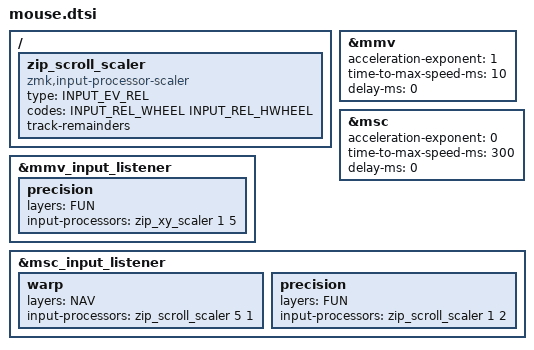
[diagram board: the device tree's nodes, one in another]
// Settings tuned for 3840 x 2160 display resolution
#define ZMK_POINTING_DEFAULT_MOVE_VAL 3000 // 600
#define ZMK_POINTING_DEFAULT_SCRL_VAL 20  // 10

#include <dt-bindings/zmk/pointing.h>
#include <input/processors.dtsi>
#include <zephyr/dt-bindings/input/input-event-codes.h>

// Based on @caksoylar's config, defaults in comments
&mmv {
  acceleration-exponent = <1>;          // 1
  time-to-max-speed-ms = <10>;          // 300
  delay-ms = <0>;                       // 0
};

&msc {
  acceleration-exponent = <0>;          // 0
  time-to-max-speed-ms = <300>;         // 300
  delay-ms = <0>;                       // 0
};

&mmv_input_listener {
  precision {
    layers = <FUN>;
    input-processors = <&zip_xy_scaler 1 5>;
  };
};

/ {
  zip_scroll_scaler: zip_scroll_scaler {
    compatible = "zmk,input-processor-scaler";
    #input-processor-cells = <2>;
    type = <INPUT_EV_REL>;
    codes = <INPUT_REL_WHEEL INPUT_REL_HWHEEL>;
    track-remainders;
  };
};

&msc_input_listener {
  warp {
    layers = <NAV>;
    input-processors = <&zip_scroll_scaler 5 1>;
  };
  precision {
    layers = <FUN>;
    input-processors = <&zip_scroll_scaler 1 2>;
  };
};

#define MS_U MOVE_UP
#define MS_D MOVE_DOWN
#define MS_L MOVE_LEFT
#define MS_R MOVE_RIGHT
#define SCRL_U SCRL_UP
#define SCRL_D SCRL_DOWN
#define SCRL_L SCRL_LEFT
#define SCRL_R SCRL_RIGHT
